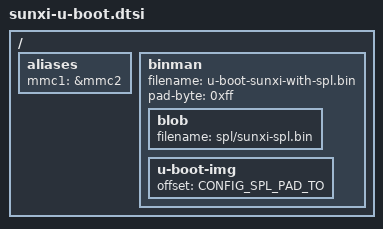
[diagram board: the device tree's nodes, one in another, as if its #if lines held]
#include <config.h>

/ {
	aliases {
#if (CONFIG_MMC_SUNXI_SLOT_EXTRA > 1)
		mmc1 = &mmc2;
#endif
	};

	binman {
		filename = "u-boot-sunxi-with-spl.bin";
		pad-byte = <0xff>;
		blob {
			filename = "spl/sunxi-spl.bin";
		};
		u-boot-img {
			offset = <CONFIG_SPL_PAD_TO>;
		};
	};
};
